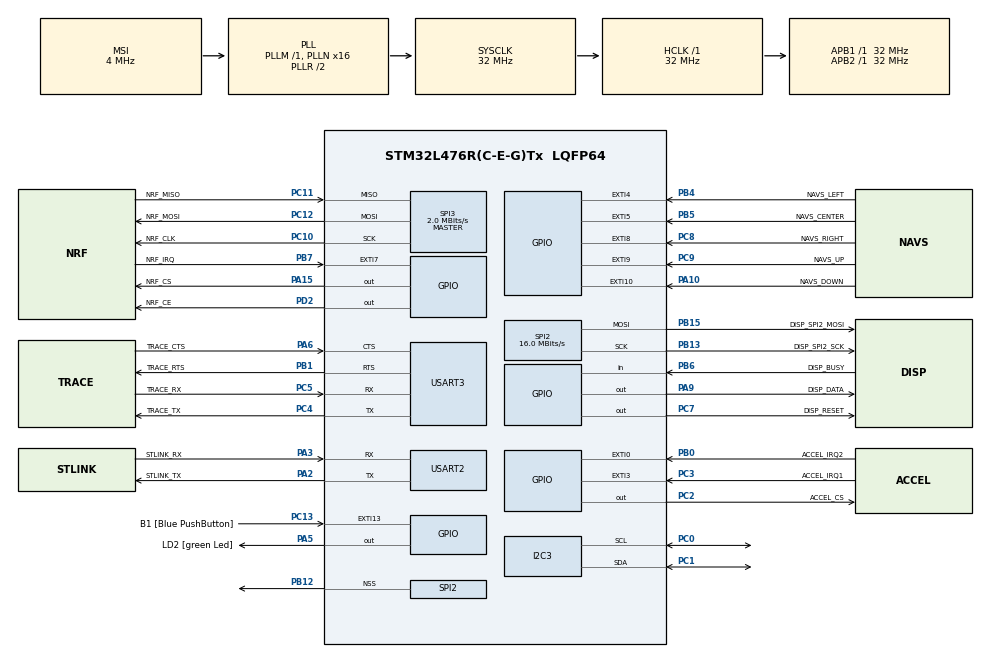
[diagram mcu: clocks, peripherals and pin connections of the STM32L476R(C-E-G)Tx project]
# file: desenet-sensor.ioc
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I2C3.I2C_Fall_Time=20
I2C3.I2C_Rise_Time=20
I2C3.Timing=0x008081B5
Mcu.Family=STM32L4
Mcu.Name=STM32L476R(C-E-G)Tx
Mcu.Package=LQFP64
NVIC.EXTI0_IRQn=true\:10\:0\:true\:false\:true\:true\:true
NVIC.EXTI15_10_IRQn=true\:10\:0\:true\:false\:true\:true\:true
NVIC.EXTI3_IRQn=true\:10\:0\:true\:false\:true\:true\:true
NVIC.EXTI4_IRQn=true\:10\:0\:true\:false\:true\:true\:true
NVIC.EXTI9_5_IRQn=true\:10\:0\:true\:false\:true\:true\:true
NVIC.PriorityGroup=NVIC_PRIORITYGROUP_4
NVIC.TIM2_IRQn=true\:3\:0\:true\:false\:true\:true\:true
PA0.GPIO_Label=ACCEL_ADC1
PA0.Signal=ADCx_IN5
PA1.GPIO_Label=ACCEL_ADC2
PA1.Signal=ADCx_IN6
PA10.GPIO_Label=NAVS_DOWN
PA10.GPIO_ModeDefaultEXTI=GPIO_MODE_IT_RISING_FALLING
PA10.Signal=GPXTI10
PA13\ (JTMS-SWDIO).GPIO_Label=TMS
PA13\ (JTMS-SWDIO).Mode=Serial_Wire
PA13\ (JTMS-SWDIO).Signal=SYS_JTMS-SWDIO
PA14\ (JTCK-SWCLK).GPIO_Label=TCK
PA14\ (JTCK-SWCLK).Mode=Serial_Wire
PA14\ (JTCK-SWCLK).Signal=SYS_JTCK-SWCLK
PA15\ (JTDI).GPIO_Label=NRF_CS
PA15\ (JTDI).Signal=GPIO_Output
PA2.GPIO_Label=STLINK_TX
PA2.GPIO_Mode=GPIO_MODE_AF_PP
PA2.GPIO_PuPd=GPIO_NOPULL
PA2.GPIO_Speed=GPIO_SPEED_FREQ_VERY_HIGH
PA2.Mode=Asynchronous
PA2.Signal=USART2_TX
PA3.GPIO_Label=STLINK_RX
PA3.GPIO_Mode=GPIO_MODE_AF_PP
PA3.GPIO_PuPd=GPIO_NOPULL
PA3.GPIO_Speed=GPIO_SPEED_FREQ_VERY_HIGH
PA3.Mode=Asynchronous
PA3.Signal=USART2_RX
PA4.GPIO_Label=ACCEL_ADC3
PA4.Signal=ADCx_IN9
PA5.GPIO_Label=LD2 [green Led]
PA5.GPIO_ModeDefaultOutputPP=GPIO_MODE_OUTPUT_PP
PA5.GPIO_PuPd=GPIO_NOPULL
PA5.GPIO_Speed=GPIO_SPEED_FREQ_LOW
PA5.Signal=GPIO_Output
PA6.GPIO_Label=TRACE_CTS
PA6.Mode=CTS_RTS
PA6.Signal=USART3_CTS
PA9.GPIO_Label=DISP_DATA
PA9.GPIO_PuPd=GPIO_PULLUP
PA9.Signal=GPIO_Output
PB0.GPIO_Label=ACCEL_IRQ2
PB0.GPIO_ModeDefaultEXTI=GPIO_MODE_IT_RISING
PB0.Signal=GPXTI0
PB1.GPIO_Label=TRACE_RTS
PB1.Mode=CTS_RTS
PB1.Signal=USART3_RTS
PB12.Mode=NSS_Signal_Hard_Output
PB12.Signal=SPI2_NSS
PB13.GPIO_Label=DISP_SPI2_SCK
PB13.Mode=TX_Only_Simplex_Unidirect_Master
PB13.Signal=SPI2_SCK
PB14.GPIO_Label=DISP_SPI2_MISO
PB14.Signal=SPI2_MISO
PB15.GPIO_Label=DISP_SPI2_MOSI
PB15.Mode=TX_Only_Simplex_Unidirect_Master
PB15.Signal=SPI2_MOSI
PB3\ (JTDO-TRACESWO).GPIO_Label=SWO
PB3\ (JTDO-TRACESWO).Signal=SYS_JTDO-SWO
PB4\ (NJTRST).GPIO_Label=NAVS_LEFT
PB4\ (NJTRST).GPIO_ModeDefaultEXTI=GPIO_MODE_IT_RISING_FALLING
PB4\ (NJTRST).Signal=GPXTI4
PB5.GPIO_Label=NAVS_CENTER
PB5.GPIO_ModeDefaultEXTI=GPIO_MODE_IT_RISING_FALLING
PB5.Signal=GPXTI5
PB6.GPIO_Label=DISP_BUSY
PB6.Signal=GPIO_Input
PB7.GPIO_Label=NRF_IRQ
PB7.GPIO_ModeDefaultEXTI=GPIO_MODE_IT_FALLING
PB7.Signal=GPXTI7
PC0.GPIO_Pu=GPIO_NOPULL
PC0.GPIO_Speed=GPIO_SPEED_FREQ_MEDIUM
PC0.Mode=I2C
PC0.Signal=I2C3_SCL
PC1.GPIO_Pu=GPIO_NOPULL
PC1.GPIO_Speed=GPIO_SPEED_FREQ_MEDIUM
PC1.Mode=I2C
PC1.Signal=I2C3_SDA
PC10.GPIO_Label=NRF_CLK
PC10.GPIO_Speed=GPIO_SPEED_FREQ_MEDIUM
PC10.Mode=Full_Duplex_Master
PC10.Signal=SPI3_SCK
PC11.GPIO_Label=NRF_MISO
PC11.GPIO_Speed=GPIO_SPEED_FREQ_MEDIUM
PC11.Mode=Full_Duplex_Master
PC11.Signal=SPI3_MISO
PC12.GPIO_Label=NRF_MOSI
PC12.GPIO_Speed=GPIO_SPEED_FREQ_MEDIUM
PC12.Mode=Full_Duplex_Master
PC12.Signal=SPI3_MOSI
PC13.GPIO_Label=B1 [Blue PushButton]
PC13.GPIO_ModeDefaultEXTI=GPIO_MODE_IT_FALLING
PC13.GPIO_PuPd=GPIO_NOPULL
PC13.Signal=GPXTI13
PC14-OSC32_IN\ (PC14).Mode=LSE-External-Oscillator
PC14-OSC32_IN\ (PC14).Signal=RCC_OSC32_IN
PC15-OSC32_OUT\ (PC15).Mode=LSE-External-Oscillator
PC15-OSC32_OUT\ (PC15).Signal=RCC_OSC32_OUT
PC2.GPIO_Label=ACCEL_CS
PC2.GPIO_ModeDefaultOutputPP=GPIO_MODE_OUTPUT_OD
PC2.PinState=GPIO_PIN_SET
PC2.Signal=GPIO_Output
PC3.GPIO_Label=ACCEL_IRQ1
PC3.GPIO_ModeDefaultEXTI=GPIO_MODE_IT_RISING
PC3.Signal=GPXTI3
PC4.GPIO_Label=TRACE_TX
PC4.Mode=Asynchronous
PC4.Signal=USART3_TX
PC5.GPIO_Label=TRACE_RX
PC5.Mode=Asynchronous
PC5.Signal=USART3_RX
PC7.GPIO_Label=DISP_RESET
PC7.GPIO_PuPd=GPIO_PULLUP
PC7.PinState=GPIO_PIN_SET
PC7.Signal=GPIO_Output
PC8.GPIO_Label=NAVS_RIGHT
PC8.GPIO_ModeDefaultEXTI=GPIO_MODE_IT_RISING_FALLING
PC8.Signal=GPXTI8
PC9.GPIO_Label=NAVS_UP
PC9.GPIO_ModeDefaultEXTI=GPIO_MODE_IT_RISING_FALLING
PC9.Signal=GPXTI9
PD2.GPIO_Label=NRF_CE
PD2.Signal=GPIO_Output
PH0-OSC_IN\ (PH0).Signal=RCC_OSC_IN
PH1-OSC_OUT\ (PH1).Signal=RCC_OSC_OUT
ProjectManager.HeapSize=0x800
ProjectManager.StackSize=0x800
ProjectManager.TargetToolchain=STM32CubeIDE
RCC.ADCFreq_Value=48000000
RCC.AHBFreq_Value=32000000
RCC.APB1Freq_Value=32000000
RCC.APB1TimFreq_Value=32000000
RCC.APB2Freq_Value=32000000
RCC.APB2TimFreq_Value=32000000
RCC.CortexFreq_Value=32000000
RCC.HCLKFreq_Value=32000000
RCC.HSE_VALUE=8000000
RCC.HSI_VALUE=16000000
RCC.MSI_VALUE=4000000
RCC.PLLN=16
RCC.PLLSAI1N=24
RCC.PREFETCH_ENABLE=1
RCC.SYSCLKFreq_VALUE=32000000
RCC.SYSCLKSource=RCC_SYSCLKSOURCE_PLLCLK
RCC.USBFreq_Value=48000000
RCC.VCOOutputFreq_Value=64000000
SH.ADCx_IN5.0=ADC1_IN5
SH.ADCx_IN6.0=ADC1_IN6
SH.ADCx_IN9.0=ADC1_IN9
SPI2.BaudRatePrescaler=SPI_BAUDRATEPRESCALER_2
SPI2.CalculateBaudRate=16.0 MBits/s
SPI2.DataSize=SPI_DATASIZE_8BIT
SPI2.Direction=SPI_DIRECTION_2LINES
SPI2.Mode=SPI_MODE_MASTER
SPI2.VirtualNSS=VM_NSSHARD
SPI2.VirtualType=VM_MASTER
SPI3.BaudRatePrescaler=SPI_BAUDRATEPRESCALER_16
SPI3.CalculateBaudRate=2.0 MBits/s
SPI3.DataSize=SPI_DATASIZE_8BIT
SPI3.Direction=SPI_DIRECTION_2LINES
SPI3.Mode=SPI_MODE_MASTER
SPI3.VirtualType=VM_MASTER
TIM2.AutoReloadPreload=TIM_AUTORELOAD_PRELOAD_DISABLE
TIM2.Channel-Output\ Compare1\ No\ Output=TIM_CHANNEL_1
TIM2.Period=1000
TIM2.Prescaler=32
TIM2.TIM_MasterOutputTrigger=TIM_TRGO_OC1REF
USART2.VirtualMode-Asynchronous=VM_ASYNC
USART3.VirtualMode-Asynchronous=VM_ASYNC
VP_TIM2_VS_ClockSourceINT.Mode=Internal
VP_TIM2_VS_no_output1.Mode=Output Compare1 No Output
board=NUCLEO-L476RG

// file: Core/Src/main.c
/* USER CODE BEGIN Header */
/**
  ******************************************************************************
  * @file           : main.c
  * @brief          : Main program body
  ******************************************************************************
  * @attention
  *
  * <h2><center>&copy; Copyright (c) 2021 STMicroelectronics.
  * All rights reserved.</center></h2>
  *
  * This software component is licensed by ST under Ultimate Liberty license
  * SLA0044, the "License"; You may not use this file except in compliance with
  * the License. You may obtain a copy of the License at:
  *                             www.st.com/SLA0044
  *
  ******************************************************************************
  */
/* USER CODE END Header */
#include "main.h"

/* USER CODE BEGIN Includes */
#include "xf/xf.h"
#include "app/factory.h"
/* USER CODE END Includes */

I2C_HandleTypeDef hi2c3;

SPI_HandleTypeDef hspi2;
SPI_HandleTypeDef hspi3;

TIM_HandleTypeDef htim2;

UART_HandleTypeDef huart2;
UART_HandleTypeDef huart3;

void SystemClock_Config(void);
static void MX_GPIO_Init(void);
static void MX_USART2_UART_Init(void);
static void MX_SPI2_Init(void);
static void MX_SPI3_Init(void);
static void MX_I2C3_Init(void);
static void MX_USART3_UART_Init(void);
static void MX_TIM2_Init(void);

int main(void)
{

  /* MCU Configuration--------------------------------------------------------*/

  /* Reset of all peripherals, Initializes the Flash interface and the Systick. */
  HAL_Init();

  /* Configure the system clock */
  SystemClock_Config();

  /* Initialize all configured peripherals */
  MX_GPIO_Init();
  MX_USART2_UART_Init();
  MX_SPI2_Init();
  MX_SPI3_Init();
  MX_I2C3_Init();
  MX_USART3_UART_Init();
  MX_TIM2_Init();
  /* USER CODE BEGIN 2 */

  Factory_init(0, NULL);
  XF_init(10);

  Factory_buildApplication();
  XF_start();

  /* USER CODE END 2 */

  /* Infinite loop */
  while (1)
  {

  }
}

void SystemClock_Config(void)
{
  RCC_OscInitTypeDef RCC_OscInitStruct = {0};
  RCC_ClkInitTypeDef RCC_ClkInitStruct = {0};

  /** Configure the main internal regulator output voltage
  */
  if (HAL_PWREx_ControlVoltageScaling(PWR_REGULATOR_VOLTAGE_SCALE1) != HAL_OK)
  {
    Error_Handler();
  }
  /** Configure LSE Drive Capability
  */
  HAL_PWR_EnableBkUpAccess();
  __HAL_RCC_LSEDRIVE_CONFIG(RCC_LSEDRIVE_LOW);
  /** Initializes the RCC Oscillators according to the specified parameters
  * in the RCC_OscInitTypeDef structure.
  */
  RCC_OscInitStruct.OscillatorType = RCC_OSCILLATORTYPE_LSE|RCC_OSCILLATORTYPE_MSI;
  RCC_OscInitStruct.LSEState = RCC_LSE_ON;
  RCC_OscInitStruct.MSIState = RCC_MSI_ON;
  RCC_OscInitStruct.MSICalibrationValue = 0;
  RCC_OscInitStruct.MSIClockRange = RCC_MSIRANGE_6;
  RCC_OscInitStruct.PLL.PLLState = RCC_PLL_ON;
  RCC_OscInitStruct.PLL.PLLSource = RCC_PLLSOURCE_MSI;
  RCC_OscInitStruct.PLL.PLLM = 1;
  RCC_OscInitStruct.PLL.PLLN = 16;
  RCC_OscInitStruct.PLL.PLLP = RCC_PLLP_DIV7;
  RCC_OscInitStruct.PLL.PLLQ = RCC_PLLQ_DIV2;
  RCC_OscInitStruct.PLL.PLLR = RCC_PLLR_DIV2;
  if (HAL_RCC_OscConfig(&RCC_OscInitStruct) != HAL_OK)
  {
    Error_Handler();
  }
  /** Initializes the CPU, AHB and APB buses clocks
  */
  RCC_ClkInitStruct.ClockType = RCC_CLOCKTYPE_HCLK|RCC_CLOCKTYPE_SYSCLK
                              |RCC_CLOCKTYPE_PCLK1|RCC_CLOCKTYPE_PCLK2;
  RCC_ClkInitStruct.SYSCLKSource = RCC_SYSCLKSOURCE_PLLCLK;
  RCC_ClkInitStruct.AHBCLKDivider = RCC_SYSCLK_DIV1;
  RCC_ClkInitStruct.APB1CLKDivider = RCC_HCLK_DIV1;
  RCC_ClkInitStruct.APB2CLKDivider = RCC_HCLK_DIV1;

  if (HAL_RCC_ClockConfig(&RCC_ClkInitStruct, FLASH_LATENCY_1) != HAL_OK)
  {
    Error_Handler();
  }
  /** Enable MSI Auto calibration
  */
  HAL_RCCEx_EnableMSIPLLMode();
}

static void MX_I2C3_Init(void)
{

  hi2c3.Instance = I2C3;
  hi2c3.Init.Timing = 0x008081B5;
  hi2c3.Init.OwnAddress1 = 0;
  hi2c3.Init.AddressingMode = I2C_ADDRESSINGMODE_7BIT;
  hi2c3.Init.DualAddressMode = I2C_DUALADDRESS_DISABLE;
  hi2c3.Init.OwnAddress2 = 0;
  hi2c3.Init.OwnAddress2Masks = I2C_OA2_NOMASK;
  hi2c3.Init.GeneralCallMode = I2C_GENERALCALL_DISABLE;
  hi2c3.Init.NoStretchMode = I2C_NOSTRETCH_DISABLE;
  if (HAL_I2C_Init(&hi2c3) != HAL_OK)
  {
    Error_Handler();
  }
  /** Configure Analogue filter
  */
  if (HAL_I2CEx_ConfigAnalogFilter(&hi2c3, I2C_ANALOGFILTER_ENABLE) != HAL_OK)
  {
    Error_Handler();
  }
  /** Configure Digital filter
  */
  if (HAL_I2CEx_ConfigDigitalFilter(&hi2c3, 0) != HAL_OK)
  {
    Error_Handler();
  }

}

static void MX_SPI2_Init(void)
{

  /* SPI2 parameter configuration*/
  hspi2.Instance = SPI2;
  hspi2.Init.Mode = SPI_MODE_MASTER;
  hspi2.Init.Direction = SPI_DIRECTION_2LINES;
  hspi2.Init.DataSize = SPI_DATASIZE_8BIT;
  hspi2.Init.CLKPolarity = SPI_POLARITY_LOW;
  hspi2.Init.CLKPhase = SPI_PHASE_1EDGE;
  hspi2.Init.NSS = SPI_NSS_HARD_OUTPUT;
  hspi2.Init.BaudRatePrescaler = SPI_BAUDRATEPRESCALER_2;
  hspi2.Init.FirstBit = SPI_FIRSTBIT_MSB;
  hspi2.Init.TIMode = SPI_TIMODE_DISABLE;
  hspi2.Init.CRCCalculation = SPI_CRCCALCULATION_DISABLE;
  hspi2.Init.CRCPolynomial = 7;
  hspi2.Init.CRCLength = SPI_CRC_LENGTH_DATASIZE;
  hspi2.Init.NSSPMode = SPI_NSS_PULSE_ENABLE;
  if (HAL_SPI_Init(&hspi2) != HAL_OK)
  {
    Error_Handler();
  }

}

static void MX_SPI3_Init(void)
{

  /* SPI3 parameter configuration*/
  hspi3.Instance = SPI3;
  hspi3.Init.Mode = SPI_MODE_MASTER;
  hspi3.Init.Direction = SPI_DIRECTION_2LINES;
  hspi3.Init.DataSize = SPI_DATASIZE_8BIT;
  hspi3.Init.CLKPolarity = SPI_POLARITY_LOW;
  hspi3.Init.CLKPhase = SPI_PHASE_1EDGE;
  hspi3.Init.NSS = SPI_NSS_SOFT;
  hspi3.Init.BaudRatePrescaler = SPI_BAUDRATEPRESCALER_16;
  hspi3.Init.FirstBit = SPI_FIRSTBIT_MSB;
  hspi3.Init.TIMode = SPI_TIMODE_DISABLE;
  hspi3.Init.CRCCalculation = SPI_CRCCALCULATION_DISABLE;
  hspi3.Init.CRCPolynomial = 7;
  hspi3.Init.CRCLength = SPI_CRC_LENGTH_DATASIZE;
  hspi3.Init.NSSPMode = SPI_NSS_PULSE_ENABLE;
  if (HAL_SPI_Init(&hspi3) != HAL_OK)
  {
    Error_Handler();
  }

}

static void MX_TIM2_Init(void)
{

  TIM_ClockConfigTypeDef sClockSourceConfig = {0};
  TIM_MasterConfigTypeDef sMasterConfig = {0};
  TIM_OC_InitTypeDef sConfigOC = {0};

  htim2.Instance = TIM2;
  htim2.Init.Prescaler = 32;
  htim2.Init.CounterMode = TIM_COUNTERMODE_UP;
  htim2.Init.Period = 1000;
  htim2.Init.ClockDivision = TIM_CLOCKDIVISION_DIV1;
  htim2.Init.AutoReloadPreload = TIM_AUTORELOAD_PRELOAD_DISABLE;
  if (HAL_TIM_Base_Init(&htim2) != HAL_OK)
  {
    Error_Handler();
  }
  sClockSourceConfig.ClockSource = TIM_CLOCKSOURCE_INTERNAL;
  if (HAL_TIM_ConfigClockSource(&htim2, &sClockSourceConfig) != HAL_OK)
  {
    Error_Handler();
  }
  if (HAL_TIM_OC_Init(&htim2) != HAL_OK)
  {
    Error_Handler();
  }
  sMasterConfig.MasterOutputTrigger = TIM_TRGO_OC1REF;
  sMasterConfig.MasterSlaveMode = TIM_MASTERSLAVEMODE_DISABLE;
  if (HAL_TIMEx_MasterConfigSynchronization(&htim2, &sMasterConfig) != HAL_OK)
  {
    Error_Handler();
  }
  sConfigOC.OCMode = TIM_OCMODE_TIMING;
  sConfigOC.Pulse = 0;
  sConfigOC.OCPolarity = TIM_OCPOLARITY_HIGH;
  sConfigOC.OCFastMode = TIM_OCFAST_DISABLE;
  if (HAL_TIM_OC_ConfigChannel(&htim2, &sConfigOC, TIM_CHANNEL_1) != HAL_OK)
  {
    Error_Handler();
  }

}

static void MX_USART2_UART_Init(void)
{

  huart2.Instance = USART2;
  huart2.Init.BaudRate = 115200;
  huart2.Init.WordLength = UART_WORDLENGTH_8B;
  huart2.Init.StopBits = UART_STOPBITS_1;
  huart2.Init.Parity = UART_PARITY_NONE;
  huart2.Init.Mode = UART_MODE_TX_RX;
  huart2.Init.HwFlowCtl = UART_HWCONTROL_NONE;
  huart2.Init.OverSampling = UART_OVERSAMPLING_16;
  huart2.Init.OneBitSampling = UART_ONE_BIT_SAMPLE_DISABLE;
  huart2.AdvancedInit.AdvFeatureInit = UART_ADVFEATURE_NO_INIT;
  if (HAL_UART_Init(&huart2) != HAL_OK)
  {
    Error_Handler();
  }

}

static void MX_USART3_UART_Init(void)
{

  huart3.Instance = USART3;
  huart3.Init.BaudRate = 115200;
  huart3.Init.WordLength = UART_WORDLENGTH_8B;
  huart3.Init.StopBits = UART_STOPBITS_1;
  huart3.Init.Parity = UART_PARITY_NONE;
  huart3.Init.Mode = UART_MODE_TX_RX;
  huart3.Init.HwFlowCtl = UART_HWCONTROL_RTS_CTS;
  huart3.Init.OverSampling = UART_OVERSAMPLING_16;
  huart3.Init.OneBitSampling = UART_ONE_BIT_SAMPLE_DISABLE;
  huart3.AdvancedInit.AdvFeatureInit = UART_ADVFEATURE_NO_INIT;
  if (HAL_UART_Init(&huart3) != HAL_OK)
  {
    Error_Handler();
  }

}

static void MX_GPIO_Init(void)
{
  GPIO_InitTypeDef GPIO_InitStruct = {0};

  /* GPIO Ports Clock Enable */
  __HAL_RCC_GPIOC_CLK_ENABLE();
  __HAL_RCC_GPIOH_CLK_ENABLE();
  __HAL_RCC_GPIOA_CLK_ENABLE();
  __HAL_RCC_GPIOB_CLK_ENABLE();
  __HAL_RCC_GPIOD_CLK_ENABLE();

  /*Configure GPIO pin Output Level */
  HAL_GPIO_WritePin(GPIOC, ACCEL_CS_Pin|DISP_RESET_Pin, GPIO_PIN_SET);

  /*Configure GPIO pin Output Level */
  HAL_GPIO_WritePin(GPIOA, LD2_Pin|DISP_DATA_Pin|NRF_CS_Pin, GPIO_PIN_RESET);

  /*Configure GPIO pin Output Level */
  HAL_GPIO_WritePin(NRF_CE_GPIO_Port, NRF_CE_Pin, GPIO_PIN_RESET);

  /*Configure GPIO pin : B1_Pin */
  GPIO_InitStruct.Pin = B1_Pin;
  GPIO_InitStruct.Mode = GPIO_MODE_IT_FALLING;
  GPIO_InitStruct.Pull = GPIO_NOPULL;
  HAL_GPIO_Init(B1_GPIO_Port, &GPIO_InitStruct);

  /*Configure GPIO pin : ACCEL_CS_Pin */
  GPIO_InitStruct.Pin = ACCEL_CS_Pin;
  GPIO_InitStruct.Mode = GPIO_MODE_OUTPUT_OD;
  GPIO_InitStruct.Pull = GPIO_NOPULL;
  GPIO_InitStruct.Speed = GPIO_SPEED_FREQ_LOW;
  HAL_GPIO_Init(ACCEL_CS_GPIO_Port, &GPIO_InitStruct);

  /*Configure GPIO pin : ACCEL_IRQ1_Pin */
  GPIO_InitStruct.Pin = ACCEL_IRQ1_Pin;
  GPIO_InitStruct.Mode = GPIO_MODE_IT_RISING;
  GPIO_InitStruct.Pull = GPIO_NOPULL;
  HAL_GPIO_Init(ACCEL_IRQ1_GPIO_Port, &GPIO_InitStruct);

  /*Configure GPIO pins : ACCEL_ADC1_Pin ACCEL_ADC2_Pin ACCEL_ADC3_Pin */
  GPIO_InitStruct.Pin = ACCEL_ADC1_Pin|ACCEL_ADC2_Pin|ACCEL_ADC3_Pin;
  GPIO_InitStruct.Mode = GPIO_MODE_ANALOG_ADC_CONTROL;
  GPIO_InitStruct.Pull = GPIO_NOPULL;
  HAL_GPIO_Init(GPIOA, &GPIO_InitStruct);

  /*Configure GPIO pins : LD2_Pin NRF_CS_Pin */
  GPIO_InitStruct.Pin = LD2_Pin|NRF_CS_Pin;
  GPIO_InitStruct.Mode = GPIO_MODE_OUTPUT_PP;
  GPIO_InitStruct.Pull = GPIO_NOPULL;
  GPIO_InitStruct.Speed = GPIO_SPEED_FREQ_LOW;
  HAL_GPIO_Init(GPIOA, &GPIO_InitStruct);

  /*Configure GPIO pin : ACCEL_IRQ2_Pin */
  GPIO_InitStruct.Pin = ACCEL_IRQ2_Pin;
  GPIO_InitStruct.Mode = GPIO_MODE_IT_RISING;
  GPIO_InitStruct.Pull = GPIO_NOPULL;
  HAL_GPIO_Init(ACCEL_IRQ2_GPIO_Port, &GPIO_InitStruct);

  /*Configure GPIO pin : DISP_RESET_Pin */
  GPIO_InitStruct.Pin = DISP_RESET_Pin;
  GPIO_InitStruct.Mode = GPIO_MODE_OUTPUT_PP;
  GPIO_InitStruct.Pull = GPIO_PULLUP;
  GPIO_InitStruct.Speed = GPIO_SPEED_FREQ_LOW;
  HAL_GPIO_Init(DISP_RESET_GPIO_Port, &GPIO_InitStruct);

  /*Configure GPIO pins : NAVS_RIGHT_Pin NAVS_UP_Pin */
  GPIO_InitStruct.Pin = NAVS_RIGHT_Pin|NAVS_UP_Pin;
  GPIO_InitStruct.Mode = GPIO_MODE_IT_RISING_FALLING;
  GPIO_InitStruct.Pull = GPIO_NOPULL;
  HAL_GPIO_Init(GPIOC, &GPIO_InitStruct);

  /*Configure GPIO pin : DISP_DATA_Pin */
  GPIO_InitStruct.Pin = DISP_DATA_Pin;
  GPIO_InitStruct.Mode = GPIO_MODE_OUTPUT_PP;
  GPIO_InitStruct.Pull = GPIO_PULLUP;
  GPIO_InitStruct.Speed = GPIO_SPEED_FREQ_LOW;
  HAL_GPIO_Init(DISP_DATA_GPIO_Port, &GPIO_InitStruct);

  /*Configure GPIO pin : NAVS_DOWN_Pin */
  GPIO_InitStruct.Pin = NAVS_DOWN_Pin;
  GPIO_InitStruct.Mode = GPIO_MODE_IT_RISING_FALLING;
  GPIO_InitStruct.Pull = GPIO_NOPULL;
  HAL_GPIO_Init(NAVS_DOWN_GPIO_Port, &GPIO_InitStruct);

  /*Configure GPIO pin : NRF_CE_Pin */
  GPIO_InitStruct.Pin = NRF_CE_Pin;
  GPIO_InitStruct.Mode = GPIO_MODE_OUTPUT_PP;
  GPIO_InitStruct.Pull = GPIO_NOPULL;
  GPIO_InitStruct.Speed = GPIO_SPEED_FREQ_LOW;
  HAL_GPIO_Init(NRF_CE_GPIO_Port, &GPIO_InitStruct);

  /*Configure GPIO pins : NAVS_LEFT_Pin NAVS_CENTER_Pin */
  GPIO_InitStruct.Pin = NAVS_LEFT_Pin|NAVS_CENTER_Pin;
  GPIO_InitStruct.Mode = GPIO_MODE_IT_RISING_FALLING;
  GPIO_InitStruct.Pull = GPIO_NOPULL;
  HAL_GPIO_Init(GPIOB, &GPIO_InitStruct);

  /*Configure GPIO pin : DISP_BUSY_Pin */
  GPIO_InitStruct.Pin = DISP_BUSY_Pin;
  GPIO_InitStruct.Mode = GPIO_MODE_INPUT;
  GPIO_InitStruct.Pull = GPIO_NOPULL;
  HAL_GPIO_Init(DISP_BUSY_GPIO_Port, &GPIO_InitStruct);

  /*Configure GPIO pin : NRF_IRQ_Pin */
  GPIO_InitStruct.Pin = NRF_IRQ_Pin;
  GPIO_InitStruct.Mode = GPIO_MODE_IT_FALLING;
  GPIO_InitStruct.Pull = GPIO_NOPULL;
  HAL_GPIO_Init(NRF_IRQ_GPIO_Port, &GPIO_InitStruct);

  /* EXTI interrupt init*/
  HAL_NVIC_SetPriority(EXTI0_IRQn, 10, 0);
  HAL_NVIC_EnableIRQ(EXTI0_IRQn);

  HAL_NVIC_SetPriority(EXTI3_IRQn, 10, 0);
  HAL_NVIC_EnableIRQ(EXTI3_IRQn);

  HAL_NVIC_SetPriority(EXTI4_IRQn, 10, 0);
  HAL_NVIC_EnableIRQ(EXTI4_IRQn);

  HAL_NVIC_SetPriority(EXTI9_5_IRQn, 10, 0);
  HAL_NVIC_EnableIRQ(EXTI9_5_IRQn);

  HAL_NVIC_SetPriority(EXTI15_10_IRQn, 10, 0);
  HAL_NVIC_EnableIRQ(EXTI15_10_IRQn);

}

void Error_Handler(void)
{
  __disable_irq();
  while (1)
  {
  }
}

/************************ (C) COPYRIGHT STMicroelectronics *****END OF FILE****/
